# edma_cc register map
Vendor: Texas Instruments
Peripheral module from a debugger description file (folder Keystone).
Registers are 32-bit, read-write, no defined reset value unless marked. A register's access mark holds for its fields unless they carry their own. Offsets are as the file gives them; lines under a group give offsets from that group; [hi:lo] are bit positions; {n}, {i} and the like mark numbered series; 'fields as' and 'values as' point back to an identical list; <NAME> marks a mode.

## EDMA2_CC
0x00 tpcc_pid access not given
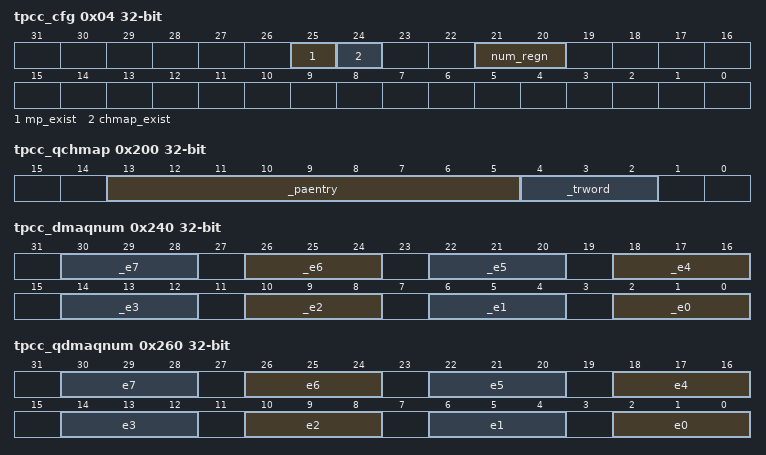
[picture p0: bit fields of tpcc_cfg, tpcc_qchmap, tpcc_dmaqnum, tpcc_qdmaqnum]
0x04 tpcc_cfg
  [25] mp_exist, [24] chmap_exist, [21:20] num_regn
0xFC tpcc_clkgdis
  [0] clkgdis
0x100 tpcc_dchmap — (1 of 64, stride 4)
  [13:5] _paentry
0x200 tpcc_qchmap — (1 of 8, stride 4)
  [13:5] _paentry, [4:2] _trword
0x240 tpcc_dmaqnum — (1 of 8, stride 4)
  [4n+2:4n] _e{n} (n=0..7)
0x260 tpcc_qdmaqnum
  [4n+2:4n] e{n} (n=0..7)
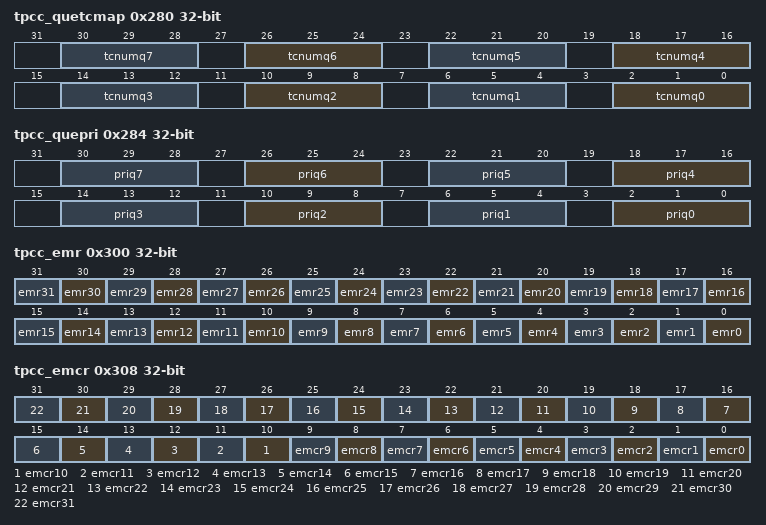
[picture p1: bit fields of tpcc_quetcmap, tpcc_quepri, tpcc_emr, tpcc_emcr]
0x280 tpcc_quetcmap
  [4n+2:4n] tcnumq{n} (n=0..7)
0x284 tpcc_quepri
  [4n+2:4n] priq{n} (n=0..7)
0x300 tpcc_emr
  [n] emr{n} (n=0..31)
0x304 tpcc_emrh access not given
0x308 tpcc_emcr
  [n] emcr{n} (n=0..31)
0x30C tpcc_emcrh access not given
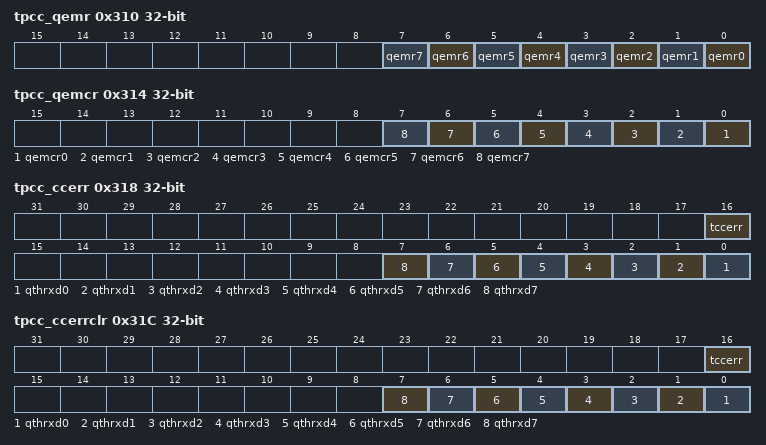
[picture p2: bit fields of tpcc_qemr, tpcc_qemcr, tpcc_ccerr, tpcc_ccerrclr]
0x310 tpcc_qemr
  [n] qemr{n} (n=0..7)
0x314 tpcc_qemcr
  [n] qemcr{n} (n=0..7)
0x318 tpcc_ccerr
  [16] tccerr, [n] qthrxd{n} (n=0..7)
0x31C tpcc_ccerrclr
  [16] tccerr, [n] qthrxd{n} (n=0..7)
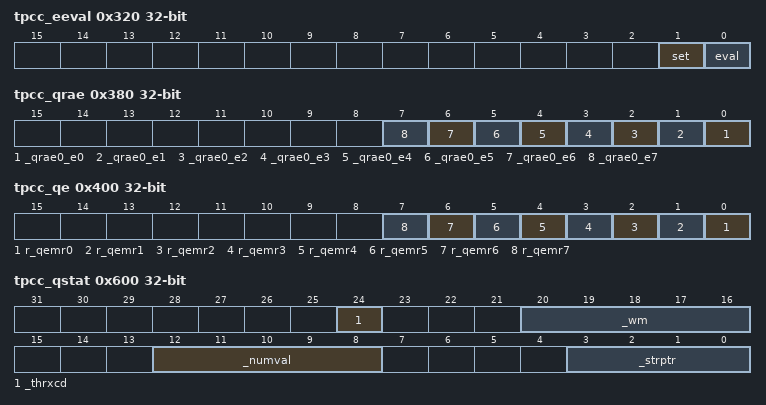
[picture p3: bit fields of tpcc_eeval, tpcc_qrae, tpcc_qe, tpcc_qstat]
0x320 tpcc_eeval
  [1] set, [0] eval
0x340 tpcc_dra_drae access not given — (1 of 8, stride 8)
0x344 tpcc_dra_draeh access not given — (1 of 8, stride 8)
0x380 tpcc_qrae — (1 of 8, stride 4)
  [n] _qrae0_e{n} (n=0..7)
0x400 tpcc_qe — (1 of 128, stride 4)
  [n] r_qemr{n} (n=0..7)
0x600 tpcc_qstat — (1 of 8, stride 4)
  [24] _thrxcd, [20:16] _wm, [12:8] _numval, [3:0] _strptr
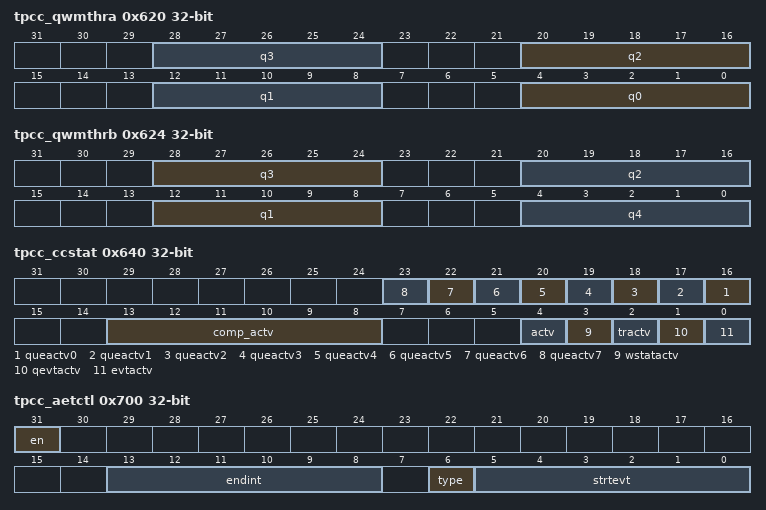
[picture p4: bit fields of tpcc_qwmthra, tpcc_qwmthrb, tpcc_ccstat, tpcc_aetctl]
0x620 tpcc_qwmthra
  [8n+4:8n] q{n} (n=0..3)
0x624 tpcc_qwmthrb
  [28:24] q3, [20:16] q2, [12:8] q1, [4:0] q4
0x640 tpcc_ccstat
  [n+16] queactv{n} (n=0..7), [13:8] comp_actv, [4] actv, [3] wstatactv, [2] tractv, [1] qevtactv, [0] evtactv
0x700 tpcc_aetctl
  [31] en, [13:8] endint, [6] type, [5:0] strtevt
0x704 tpcc_aetstat
  [0] stat
0x708 tpcc_aetcmd
  [0] clr
0x800 tpcc_mpfar
  [31:0] faddr
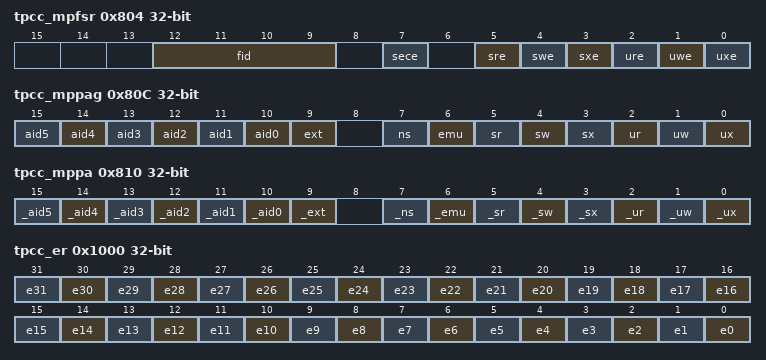
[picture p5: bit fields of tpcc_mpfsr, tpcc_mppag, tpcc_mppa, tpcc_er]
0x804 tpcc_mpfsr
  [12:9] fid, [7] sece, [5] sre, [4] swe, [3] sxe, [2] ure, [1] uwe, [0] uxe
0x808 tpcc_mpfcr
  [0] mpfclr
0x80C tpcc_mppag
  [n+10] aid{n} (n=0..5), [9] ext, [7] ns, [6] emu, [5] sr, [4] sw, [3] sx, [2] ur, [1] uw, [0] ux
0x810 tpcc_mppa — (1 of 8, stride 4)
  [n+10] _aid{n} (n=0..5), [9] _ext, [7] _ns, [6] _emu, [5] _sr, [4] _sw, [3] _sx, [2] _ur, [1] _uw, [0] _ux
0x1000 tpcc_er
  [n] e{n} (n=0..31)
0x1004 tpcc_erh access not given
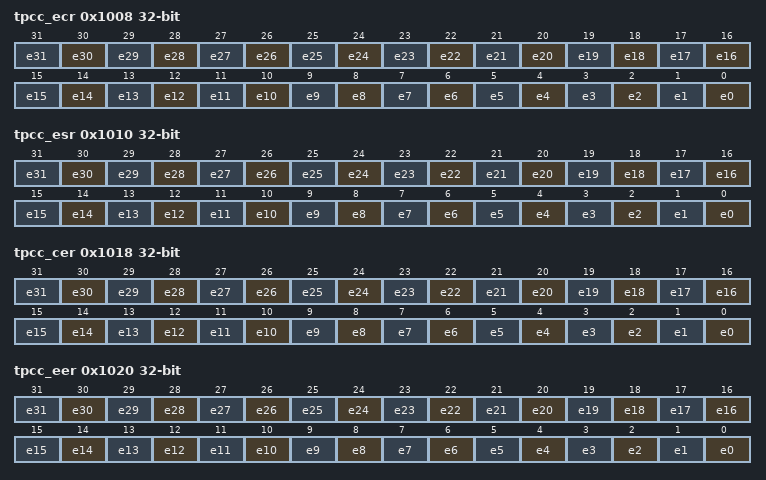
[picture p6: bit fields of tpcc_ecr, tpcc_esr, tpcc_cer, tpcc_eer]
0x1008 tpcc_ecr
  [n] e{n} (n=0..31)
0x100C tpcc_ecrh access not given
0x1010 tpcc_esr
  [n] e{n} (n=0..31)
0x1014 tpcc_esrh access not given
0x1018 tpcc_cer
  [n] e{n} (n=0..31)
0x101C tpcc_cerh access not given
0x1020 tpcc_eer
  [n] e{n} (n=0..31)
0x1024 tpcc_eerh access not given
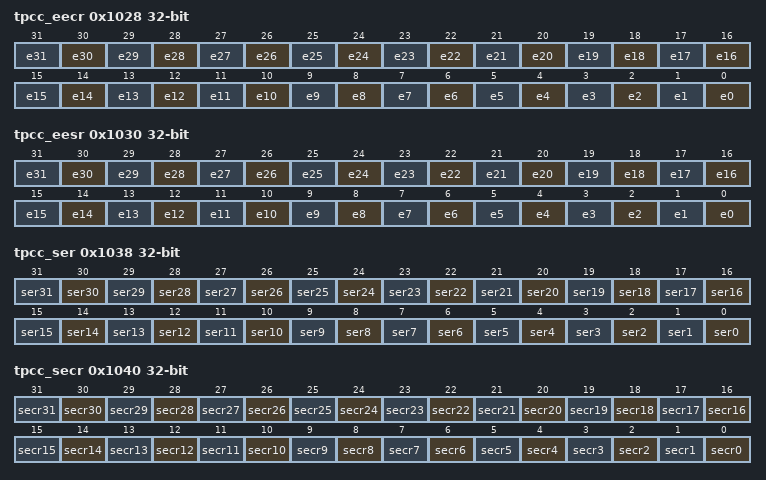
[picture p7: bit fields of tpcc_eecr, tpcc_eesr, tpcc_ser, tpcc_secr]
0x1028 tpcc_eecr
  [n] e{n} (n=0..31)
0x102C tpcc_eecrh access not given
0x1030 tpcc_eesr
  [n] e{n} (n=0..31)
0x1034 tpcc_eesrh access not given
0x1038 tpcc_ser
  [n] ser{n} (n=0..31)
0x103C tpcc_serh access not given
0x1040 tpcc_secr
  [n] secr{n} (n=0..31)
0x1044 tpcc_secrh access not given
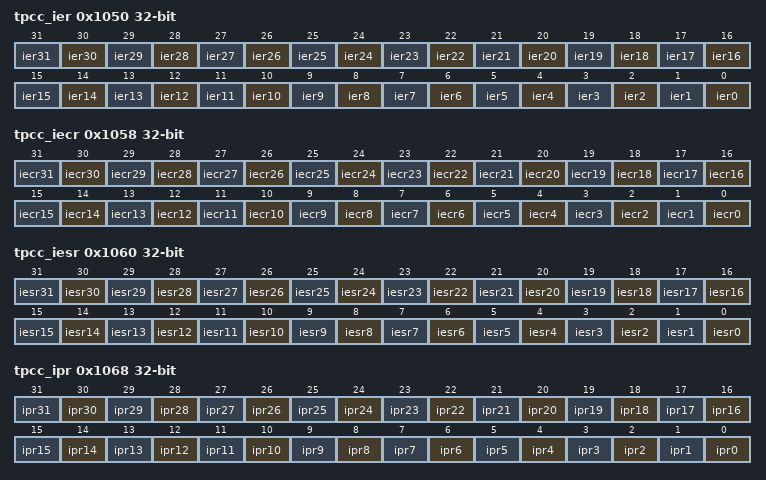
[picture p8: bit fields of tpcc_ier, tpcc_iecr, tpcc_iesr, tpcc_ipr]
0x1050 tpcc_ier
  [n] ier{n} (n=0..31)
0x1054 tpcc_ierh access not given
0x1058 tpcc_iecr
  [n] iecr{n} (n=0..31)
0x105C tpcc_iecrh access not given
0x1060 tpcc_iesr
  [n] iesr{n} (n=0..31)
0x1064 tpcc_iesrh access not given
0x1068 tpcc_ipr
  [n] ipr{n} (n=0..31)
0x106C tpcc_iprh access not given
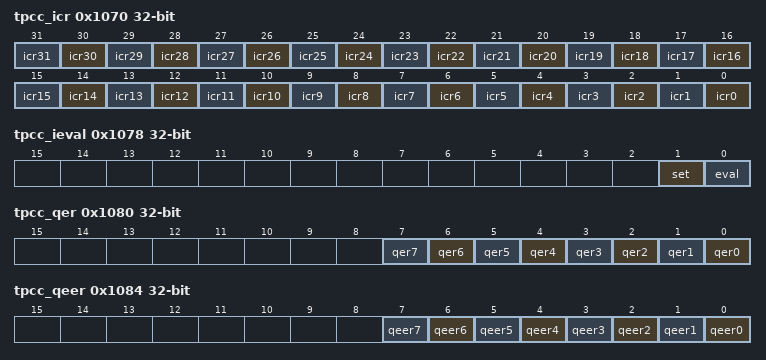
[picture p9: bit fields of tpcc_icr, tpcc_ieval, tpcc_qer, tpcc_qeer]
0x1070 tpcc_icr
  [n] icr{n} (n=0..31)
0x1074 tpcc_icrh access not given
0x1078 tpcc_ieval
  [1] set, [0] eval
0x1080 tpcc_qer
  [n] qer{n} (n=0..7)
0x1084 tpcc_qeer
  [n] qeer{n} (n=0..7)
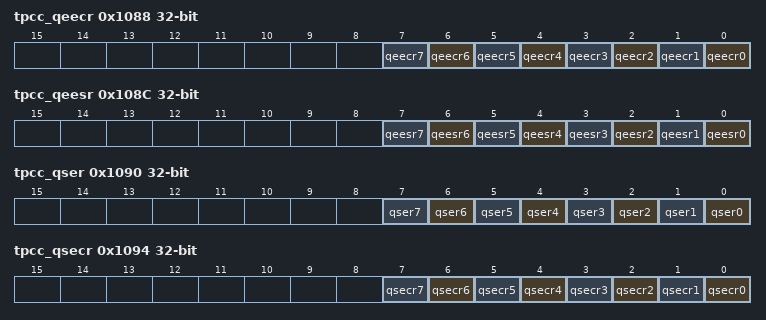
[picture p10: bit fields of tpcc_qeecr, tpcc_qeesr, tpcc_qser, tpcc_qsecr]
0x1088 tpcc_qeecr
  [n] qeecr{n} (n=0..7)
0x108C tpcc_qeesr
  [n] qeesr{n} (n=0..7)
0x1090 tpcc_qser
  [n] qser{n} (n=0..7)
0x1094 tpcc_qsecr
  [n] qsecr{n} (n=0..7)
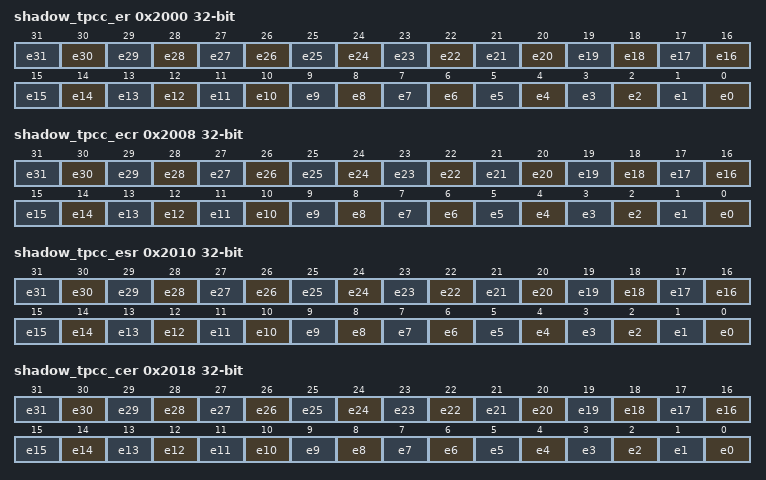
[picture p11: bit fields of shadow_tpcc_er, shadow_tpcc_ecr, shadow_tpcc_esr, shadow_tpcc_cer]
0x2000 shadow_tpcc_er — (1 of 8, stride 512)
  [n] e{n} (n=0..31)
0x2004 shadow_tpcc_erh access not given — (1 of 8, stride 512)
0x2008 shadow_tpcc_ecr — (1 of 8, stride 512)
  [n] e{n} (n=0..31)
0x200C shadow_tpcc_ecrh access not given — (1 of 8, stride 512)
0x2010 shadow_tpcc_esr — (1 of 8, stride 512)
  [n] e{n} (n=0..31)
0x2014 shadow_tpcc_esrh access not given — (1 of 8, stride 512)
0x2018 shadow_tpcc_cer — (1 of 8, stride 512)
  [n] e{n} (n=0..31)
0x201C shadow_tpcc_cerh access not given — (1 of 8, stride 512)
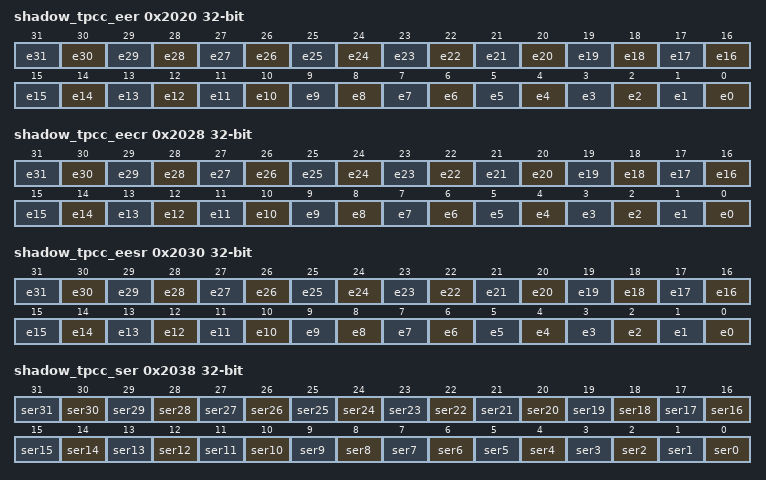
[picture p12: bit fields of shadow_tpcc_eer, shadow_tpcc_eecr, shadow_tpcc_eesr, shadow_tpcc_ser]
0x2020 shadow_tpcc_eer — (1 of 8, stride 512)
  [n] e{n} (n=0..31)
0x2024 shadow_tpcc_eerh access not given — (1 of 8, stride 512)
0x2028 shadow_tpcc_eecr — (1 of 8, stride 512)
  [n] e{n} (n=0..31)
0x202C shadow_tpcc_eecrh access not given — (1 of 8, stride 512)
0x2030 shadow_tpcc_eesr — (1 of 8, stride 512)
  [n] e{n} (n=0..31)
0x2034 shadow_tpcc_eesrh access not given — (1 of 8, stride 512)
0x2038 shadow_tpcc_ser — (1 of 8, stride 512)
  [n] ser{n} (n=0..31)
0x203C shadow_tpcc_serh access not given — (1 of 8, stride 512)
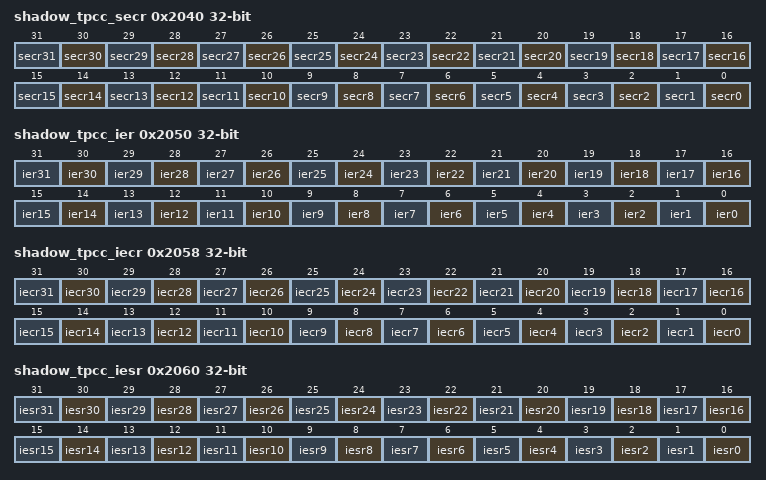
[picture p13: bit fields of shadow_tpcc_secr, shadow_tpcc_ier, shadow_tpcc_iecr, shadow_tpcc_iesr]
0x2040 shadow_tpcc_secr — (1 of 8, stride 512)
  [n] secr{n} (n=0..31)
0x2044 shadow_tpcc_secrh access not given — (1 of 8, stride 512)
0x2050 shadow_tpcc_ier — (1 of 8, stride 512)
  [n] ier{n} (n=0..31)
0x2054 shadow_tpcc_ierh access not given — (1 of 8, stride 512)
0x2058 shadow_tpcc_iecr — (1 of 8, stride 512)
  [n] iecr{n} (n=0..31)
0x205C shadow_tpcc_iecrh access not given — (1 of 8, stride 512)
0x2060 shadow_tpcc_iesr — (1 of 8, stride 512)
  [n] iesr{n} (n=0..31)
0x2064 shadow_tpcc_iesrh access not given — (1 of 8, stride 512)
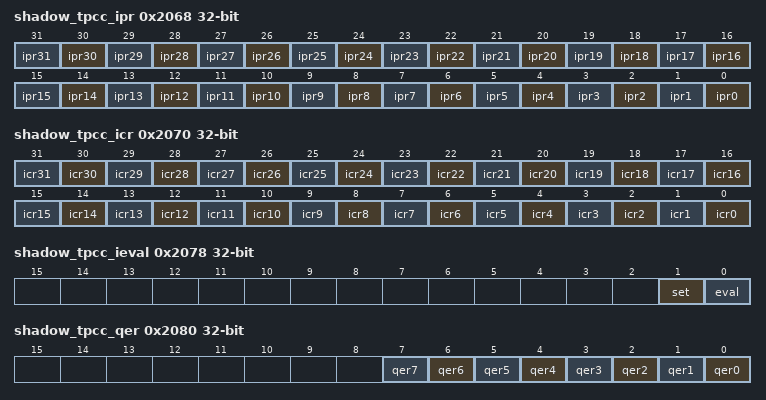
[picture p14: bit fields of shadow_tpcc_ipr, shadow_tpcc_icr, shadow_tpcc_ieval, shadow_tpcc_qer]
0x2068 shadow_tpcc_ipr — (1 of 8, stride 512)
  [n] ipr{n} (n=0..31)
0x206C shadow_tpcc_iprh access not given — (1 of 8, stride 512)
0x2070 shadow_tpcc_icr — (1 of 8, stride 512)
  [n] icr{n} (n=0..31)
0x2074 shadow_tpcc_icrh access not given — (1 of 8, stride 512)
0x2078 shadow_tpcc_ieval — (1 of 8, stride 512)
  [1] set, [0] eval
0x2080 shadow_tpcc_qer — (1 of 8, stride 512)
  [n] qer{n} (n=0..7)
0x2084 shadow_tpcc_qeer — (1 of 8, stride 512)
  [n] qeer{n} (n=0..7)
0x2088 shadow_tpcc_qeecr — (1 of 8, stride 512)
  [n] qeecr{n} (n=0..7)
0x208C shadow_tpcc_qeesr — (1 of 8, stride 512)
  [n] qeesr{n} (n=0..7)
0x2090 shadow_tpcc_qser — (1 of 8, stride 512)
  [n] qser{n} (n=0..7)
0x2094 shadow_tpcc_qsecr — (1 of 8, stride 512)
  [n] qsecr{n} (n=0..7)
0x4000 paramset_opt access not given — (1 of 512, stride 32)
0x4004 paramset_src access not given — (1 of 512, stride 32)
0x4008 paramset_a_b_cnt access not given — (1 of 512, stride 32)
0x400C paramset_dst access not given — (1 of 512, stride 32)
0x4010 paramset_src_dst_bidx access not given — (1 of 512, stride 32)
0x4014 paramset_link_bcntrld access not given — (1 of 512, stride 32)
0x4018 paramset_src_dst_cidx access not given — (1 of 512, stride 32)
0x401C paramset_ccnt access not given — (1 of 512, stride 32)
